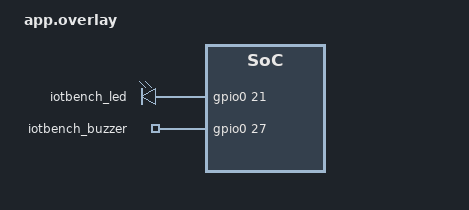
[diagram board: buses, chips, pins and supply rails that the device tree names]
&i2c0 {
	compatible = "nordic,nrf-twi";
};

/ {
	iotbench_gpios {
		compatible = "gpio-leds";
		iotbench_led: iotbench_led {
			gpios = <&gpio0 21 GPIO_ACTIVE_HIGH>;
		};
		iotbench_buzzer: iotbench_buzzer {
			gpios = <&gpio0 27 GPIO_ACTIVE_HIGH>;
		};
	};
	aliases {
		my-led = &iotbench_led;
		my-buzzer = &iotbench_buzzer;
	};
};
